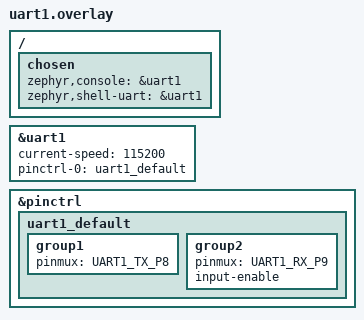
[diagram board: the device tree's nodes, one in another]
/ {
    chosen {
        zephyr,console = &uart1;
        zephyr,shell-uart = &uart1;
    };
};

&uart1 {
    current-speed = <115200>;
    status = "okay";
    pinctrl-0 = <&uart1_default>;
    pinctrl-names = "default";
};

&pinctrl {
    uart1_default: uart1_default {
        group1 {
            pinmux = <UART1_TX_P8>;
        };
        group2 {
            pinmux = <UART1_RX_P9>;
            input-enable;
        };
    };
};
